# ARMv8M-Extended register map
Registers are read-only, no defined reset value unless marked. A register's access mark holds for its fields unless they carry their own. Offsets are from the block's base; lines under a group give offsets from that group; [hi:lo] are bit positions; {n}, {i} and the like mark numbered series; 'fields as' and 'values as' point back to an identical list; <NAME> marks a mode.

## Memory map
0xE0003000 PMU_Ext size 0x4000 — Performance Monitoring Unit Extension
0xE000E010 SYSTICK size 0x10 — SysTick Timer
0xE000ED90 MPU size 0x34 — Memory Protection Unit
0xE000EDD0 SAU size 0x1C — Security Attribution Unit
0xE000EF50 CMO size 0x2C — Cache Maintenance Operations
0xE001E300 PMC size 0x8 — Implementation defined power mode control
0xE001E400 EWIC_IStat size 0x504 — External Wakeup Interrupt Controller Interrupt Status Access
0xE001E500 TCM_SecGate size 0x150 — TCM Security Gate
0xE001E700 PCI size 0x8 — Implementation defined processor configuration information
0xE0047000 EWIC_Ctrl size 0x800 — External Wakeup Interrupt Controller
0xE0047F00 EWIC_CoreSight size 0x1000 — External Wakeup Interrupt Controller CoreSight registers

## CMO — Cache Maintenance Operations
Base 0xE000EF50
0x00 ICIALLU wo — Instruction Cache Invalidate All to PoU invalidates all instruction caches to Point of Unification (PoU)
  [31:0] Ignored — The value written to this field is ignored
0x08 ICIMVAU wo — Instruction Cache line Invalidate by Address to PoU invalidates instruction cache lines by address to Point of Unification (PoU)
  [31:0] ADDRESS — Writing to this field initiates the maintenance operation for the address that is written
0x0C DCIMVAC wo — Data Cache line Invalidate by Address to PoC invalidates data or unified cache lines by address to Point of Coherency (PoC)
  fields as ICIMVAU
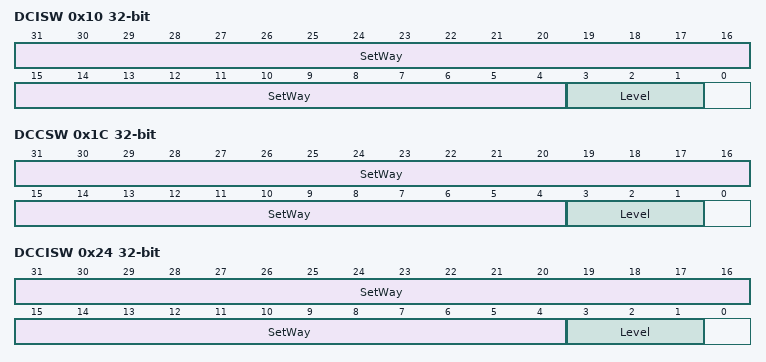
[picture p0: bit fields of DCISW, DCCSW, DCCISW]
0x10 DCISW wo — Data Cache line Invalidate by Set/Way invalidates instruction cache lines by address to Point of Unification (PoU)
  [31:4] SetWay — Cache set/way. Contains two fields: Way, bits[31:32-A], the number of the way to operate on. Set, bits[B-1:L], the number of the set to operate on.
  [3:1] Level — Cache level. This field is 0b000.
0x14 DCCMVAU wo — Data cache clean by address to the PoU cleans data or unified cache lines by address to Point of Unification (PoU)
  fields as ICIMVAU
0x18 DCCMVAC wo — Data cache line clean by address to the PoC cleans data or unified cache lines by address to Point of Unification (PoC)
  fields as ICIMVAU
0x1C DCCSW wo — Data Cache Clean line by Set/Way cleans data or unified cache line by set/way
  [31:4] SetWay — Contains two fields: Way, bits [31:32-A], the number of the way to operate on. Set, bits [B-1:L], the number of the set to operate on.
  [3:1] Level — Cache level. This field is 0b000
0x20 DCCIMVAC wo — Data Cache Clean and Invalidate by Address to the PoC cleans data or unified cache lines by address to Point of Coherency (PoC)
  fields as ICIMVAU
0x24 DCCISW wo — Data Cache Clean and Invalidate by Set/Way cleans and invalidates data or unified cache line by set/way
  [31:4] SetWay — Contains two fields: Way, bits[31:32-A], the number of the way to operate on. Set, bits[B-1:L], the number of the set to operate on.
  [3:1] Level — Cache level. This field is 0b000.
0x28 BPIALL wo — Branch Predictor Invalidate All invalidates all entries from branch predictors
  [31:0] Ignored — The value written to this field is ignored

## EWIC_Ctrl — External Wakeup Interrupt Controller
Base 0xE0047000
0x00 EWIC_CR rw — EWIC Control Register the main External Wakeup Interrupt Controller (EWIC) control register
  [0] EN — Enable
    0=EWIC is disabled, events are not pended, and WAKEUP is not signaled; 1=EWIC is enabled, events are pended, and WAKEUP is signaled
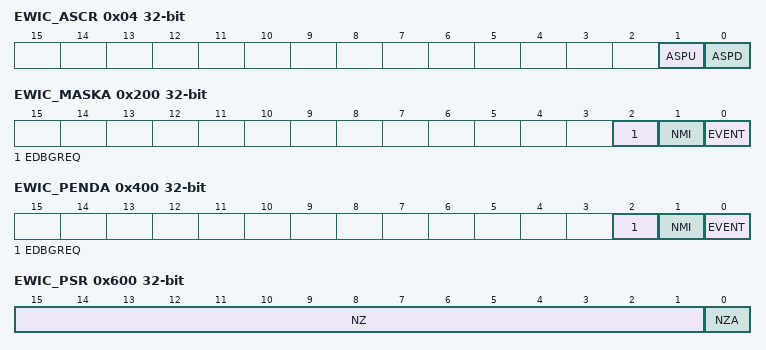
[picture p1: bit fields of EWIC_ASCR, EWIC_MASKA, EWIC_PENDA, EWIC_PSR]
0x04 EWIC_ASCR rw — EWIC Automatic Sequence Control Register determines whether the processor generates APB transactions on entry and exit from Wakeup Interrupt Controller (WIC) sleep to set up the wakeup state in the External Wakeup Interrupt Controller (EWIC)
  [1] ASPU — The processor must use this value to decide whether any automatic EWIC accesses must be performed on transitioning from a low-power state
    0=No automatic sequence on power up; 1=Automatic sequence on powerup
  [0] ASPD — The processor must use this value to decide whether any automatic EWIC accesses must be performed on transitioning to a low-power state
    0=No automatic sequence on entry to a low-power state; 1=Automatic sequence on entry to a low-power state
0x08 EWIC_CLRMASK wo — EWIC Clear Mask Register causes EWIC_MASKA and all the EWIC_MASKn registers to be cleared. The write data is ignored. This register is RAZ.
0x0C EWIC_NUMID — EWIC Event Number ID Register returns the total number of events supported in the External Wakeup Interrupt Controller (EWIC) that have been configured during synthesis
  [15:0] NUMEVENT — The number of events supported
0x200 EWIC_MASKA rw — EWIC Mask Registers defines the mask for special events and the EWIC_MASKn registers for external interrupt (IRQ) events
  [2] EDBGREQ — Mask for external debug request
  [1] NMI — Mask for Non-Maskable Interrupt (NMI)
  [0] EVENT — Mask for Wait For Exception (WFE) wakeup event
{0x204+4i} EWIC Mask Registers[{i}] (i=0..14) rw — Defines the mask for special events and the EWIC_MASKn registers for external interrupt (IRQ) events
  [31:0] IRQ — Masks for interrupts (nx32) to ((n+1)x32)-1
0x400 EWIC_PENDA — EWIC Pend Event Registers indicate which events have been pended
  [2] EDBGREQ — External debug request is pended
  [1] NMI — Non-Maskable Interrupt (NMI) is pended
  [0] EVENT — Wait For Exception (WFE) wakeup event is pended
{0x404+4i} EWIC Pend Event Registers[{i}] (i=0..14) rw — Indicate which events have been pended
  [31:0] IRQ — Interrupts (nx32) to ((n+1)x32)-1 are pended. A write of zero to this field is ignored.
0x600 EWIC_PSR — EWIC Pend Summary Register indicates which EWIC_PENDn registers are non-zero
  [15:1] NZ — If EWIC_PSR.NZ[n+1] is set, then EWIC_PENDn is non-zero
  [0] NZA — If EWIC_PSR.NZA set, then EWIC_PENDA is non-zero
